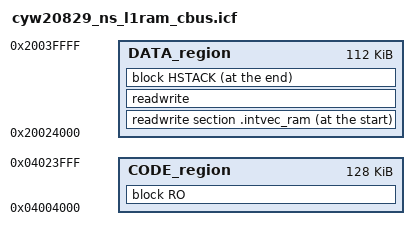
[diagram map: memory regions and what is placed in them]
/*******************************************************************************
* \file cyw20829_ns_ram_cbus.icf
* \version 1.1.0
*
* Linker file for the IAR compiler.
*
* The main purpose of the linker script is to describe how the sections in the
* input files should be mapped into the output file, and to control the memory
* layout of the output file.
*
* \note The entry point is fixed and starts at 0x20004000. The valid application
* image should be placed there.
*
* \note The linker files included with the PDL template projects must be generic
* and handle all common use cases. Your project may not use every section
* defined in the linker files. In that case you may see warnings during the
* build process. In your project, you can simply comment out or remove the
* relevant code in the linker file.
*
********************************************************************************
* \copyright
* Copyright 2021 Cypress Semiconductor Corporation
* SPDX-License-Identifier: Apache-2.0
*
* Licensed under the Apache License, Version 2.0 (the "License");
* you may not use this file except in compliance with the License.
* You may obtain a copy of the License at
*
*     http://www.apache.org/licenses/LICENSE-2.0
*
* Unless required by applicable law or agreed to in writing, software
* distributed under the License is distributed on an "AS IS" BASIS,
* WITHOUT WARRANTIES OR CONDITIONS OF ANY KIND, either express or implied.
* See the License for the specific language governing permissions and
* limitations under the License.
*******************************************************************************/

/* The size of the stack section at the end of CM33 SRAM */
define symbol STACK_SIZE = 0x1000;
define symbol HEAP_SIZE = 0x0400;


define symbol FLASH_START_ADDR_SAHB         = 0x60000000;
define symbol FLASH_START_ADDR_CBUS         = 0x08000000;
define symbol RAM_START_ADDR_SAHB           = 0x20000000;
define symbol RAM_START_ADDR_CBUS           = 0x04000000;
define symbol RAM_END_ADDR_SAHB             = 0x20040000; /* 256K */
define symbol FLASH_END_ADDR_SAHB           = 0x60080000; /* 512K */

define symbol BOOTSTRAP_OFFSET_FLASH        = 0x00000048; /* toc2=0x10, l1_desc=0x18, sign_header=0x20 */
define symbol BOOTSTRAP_OFFSET_RAM          = 0x00004000;
define symbol APPCODE_OFFSET_FLASH          = 0x00000000;

/* vma for bootstrap code region */
define symbol CODE_VMA                      = RAM_START_ADDR_CBUS + BOOTSTRAP_OFFSET_RAM; /* 0x04004000 */
/* lma for bootstrap code region */
define symbol CODE_LMA                      = FLASH_START_ADDR_SAHB + BOOTSTRAP_OFFSET_FLASH; /* 0x60000048 */
/* bootstrap code size */
define symbol CODE_SIZE                     = 0x00020000;

/* vma for bootstrap data region */
define symbol DATA_VMA                      = RAM_START_ADDR_SAHB + BOOTSTRAP_OFFSET_RAM + CODE_SIZE; /* 0x20024000 */
/* lma for bootstrap data region */
define symbol DATA_LMA                      = CODE_LMA + CODE_SIZE; /* 0x60020048 */
/* bootstrap data size */
define symbol DATA_SIZE                     = RAM_END_ADDR_SAHB - DATA_VMA; /* 112K */


/* The symbols below define the location and size of blocks of memory in the target.
 * Use these symbols to specify the memory regions available for allocation.
 */

/*-Sizes-*/
if (!isdefinedsymbol(__STACK_SIZE)) {
  define symbol __size_cstack__ = STACK_SIZE;
} else {
  define symbol __size_cstack__ = __STACK_SIZE;
}
define symbol __size_proc_stack__ = 0x0;

/* Defines the minimum heap size. The actual heap size will be expanded to the end of the stack region */
if (!isdefinedsymbol(__HEAP_SIZE)) {
    define symbol __size_heap__ = HEAP_SIZE;
} else {
  define symbol __size_heap__ = __HEAP_SIZE;
}

define memory mem with size = 4G;
define region CODE_region = mem:[from CODE_VMA size CODE_SIZE];
define region DATA_region = mem:[from DATA_VMA size DATA_SIZE];

define block CSTACK     with alignment = 8, size = __size_cstack__     { };
define block PROC_STACK with alignment = 8, size = __size_proc_stack__ { };
define block HEAP       with expanding size, alignment = 8, minimum size = __size_heap__ { };
define block HSTACK {block HEAP, block PROC_STACK, last block CSTACK};
define block RO     {first section .intvec, readonly};


/*-Initializations-*/
initialize by copy { readwrite };
do not initialize  { section .noinit, section .intvec_ram };

/*-Placement-*/

/* CODE */
place in          CODE_region  { block RO };


/* RAM */
place at start of DATA_region  { readwrite section .intvec_ram};
place in          DATA_region  { readwrite };
place at end   of DATA_region  { block HSTACK };


keep {  section .intvec  };

define exported symbol __bootstrap_start_addr__        = RAM_START_ADDR_SAHB + BOOTSTRAP_OFFSET_RAM;
/* EOF */
